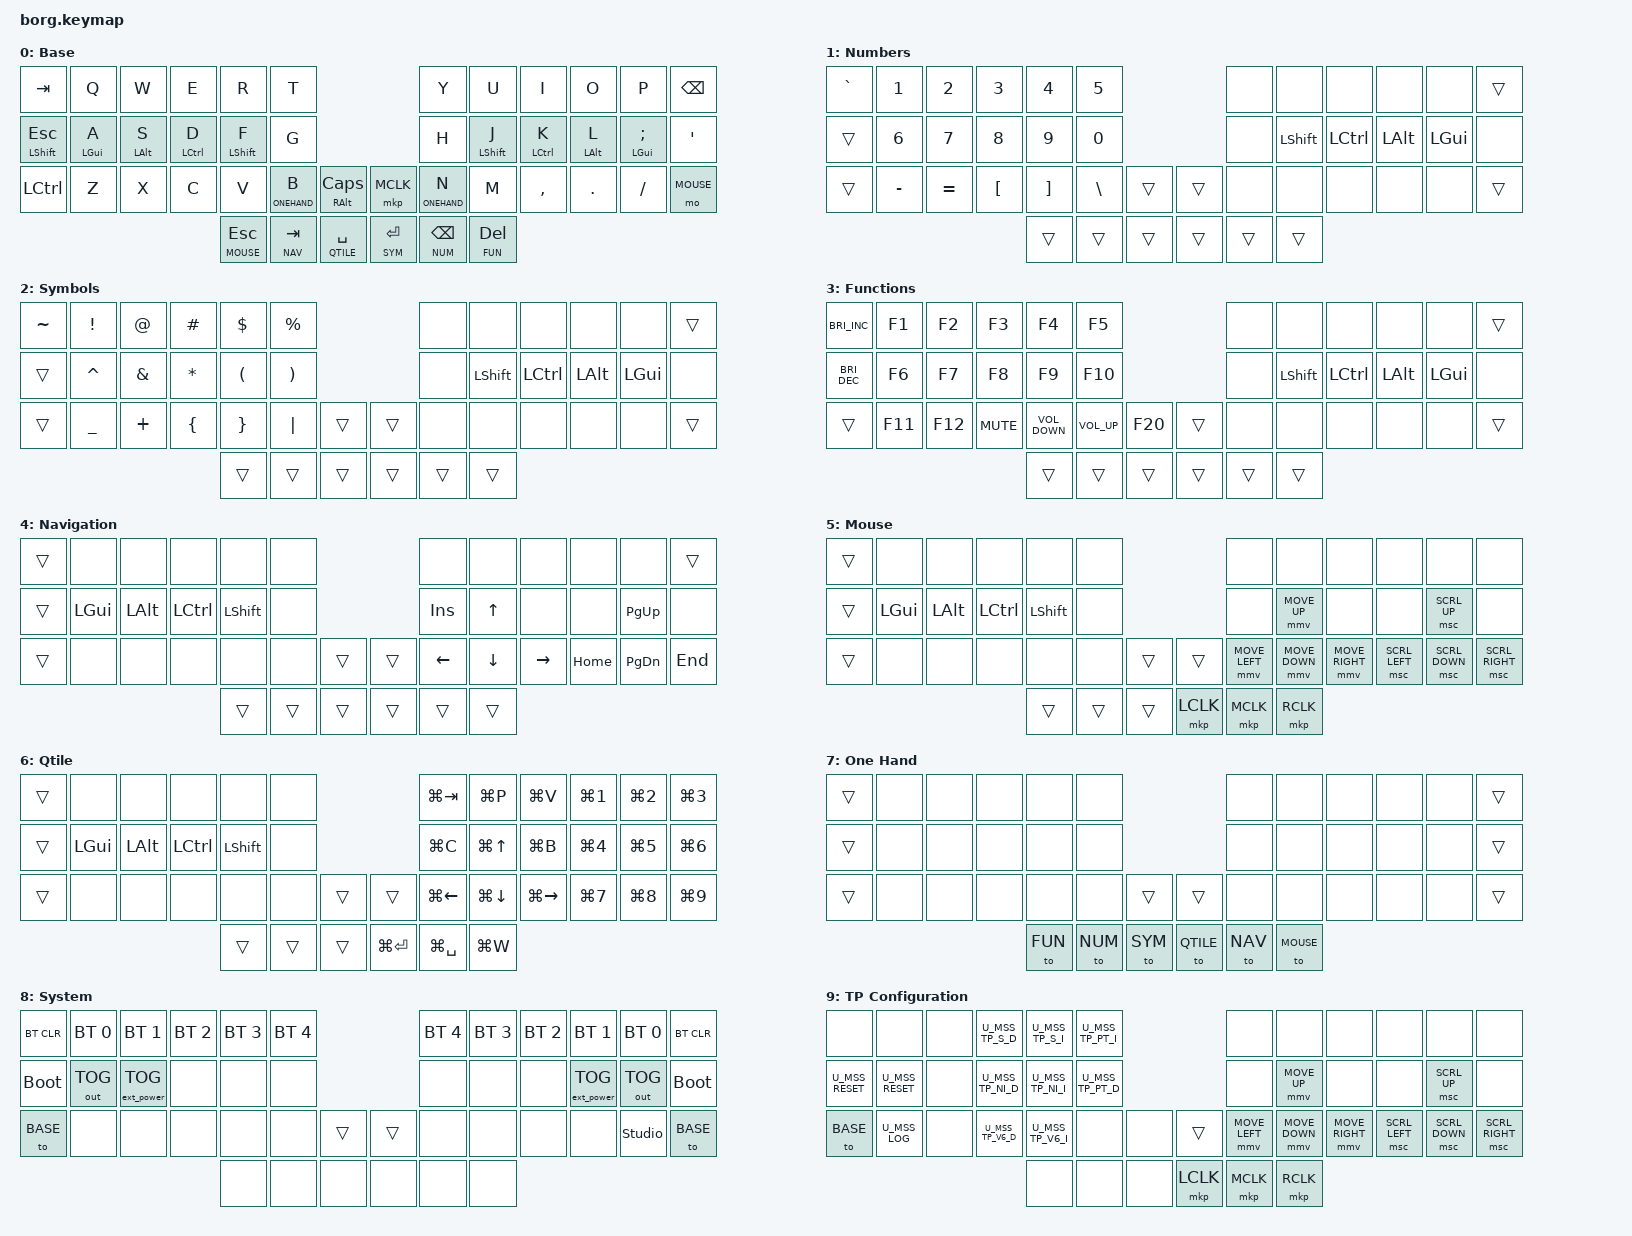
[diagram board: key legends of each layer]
/*
 * Copyright (c) 2020 The ZMK Contributors
 *
 * SPDX-License-Identifier: MIT
 */

#define BASE 0
#define NUM 1
#define SYM 2
#define FUN 3
#define NAV 4
#define MOUSE 5
#define QTILE 6
#define ONEHAND 7
#define SYS 8
#define TPCONF 9

// Change mouse default parameters
//#define ZMK_POINTING_DEFAULT_MOVE_VAL 1200  // 600
#define ZMK_POINTING_DEFAULT_SCRL_VAL 25   // 10

#include <input/processors.dtsi>
#include <behaviors.dtsi>
#include <dt-bindings/zmk/keys.h>
#include <dt-bindings/zmk/bt.h>
#include <dt-bindings/zmk/pointing.h>
#include <dt-bindings/zmk/outputs.h>
#include <dt-bindings/zmk/mouse.h>
#include <behaviors/mouse_keys.dtsi>
#include "include/mouse_tp.dtsi"
#include <dt-bindings/zmk/ext_power.h>

// Double the speed of scrolling
&msc_input_listener { input-processors = <&zip_scroll_scaler 2 1>; };

/*
    &msc {
        acceleration-exponent = <1>;      // 0
        time-to-max-speed-ms = <100>;       // 300
        delay-ms = <0>;                   // 0
    };
*/

// Disable line-wrap in your editor to see a "visualization" of the key layouts
/ {
    combos {
        compatible = "zmk,combos";

        combo_base_layer_right {
            timeout-ms = <50>;
            key-positions = <32 33>;
            bindings = <&to BASE>;
        };
        combo_base_layer_left {
            timeout-ms = <50>;
            key-positions = <28 29>;
            bindings = <&to BASE>;
        };
        combo_sys_layer {
            timeout-ms = <50>;
            key-positions = <18 32>;
            bindings = <&to SYS>;
        };
        combo_tpconf_layer {
            timeout-ms = <50>;
            key-positions = <19 33>;
            bindings = <&to TPCONF>;
        };
    };

    behaviors {
        mouse_wheel: mouse_wheel {
            compatible = "zmk,behavior-sensor-rotate";
            #sensor-binding-cells = <0>;
            bindings = <&msc SCRL_UP>, <&msc SCRL_DOWN>;
            tap-ms = <100>;
        };

        u_lt: u_layer_tap {
            compatible = "zmk,behavior-hold-tap";
            #binding-cells = <2>;
            flavor = "tap-preferred";
            tapping-term-ms = <200>;
            quick-tap-ms = <200>;
            bindings = < &mo >, < &kp >;
        };

        u_mt: u_mod_tap {
            compatible = "zmk,behavior-hold-tap";
            #binding-cells = <2>;
            flavor = "balanced";
            tapping-term-ms = <150>;
            bindings = < &kp >, < &kp >;
        };

    };

    keymap {
        compatible = "zmk,keymap";

        Base_layer {
            display-name = "Base";
            bindings = <
//     ╭────────────────────────┬────────────────────────┬────────────────────────┬────────────────────────┬────────────────────────┬────────────────────────╮                                                      ╭────────────────────────┬────────────────────────┬────────────────────────┬────────────────────────┬────────────────────────┬────────────────────────╮
         &kp TAB                  &kp Q                    &kp W                    &kp E                    &kp R                    &kp T                                                                           &kp Y                    &kp U                    &kp I                    &kp O                    &kp P                    &kp BSPC
//     ├────────────────────────┼────────────────────────┼────────────────────────┼────────────────────────┼────────────────────────┼────────────────────────┤                                                      ├────────────────────────┼────────────────────────┼────────────────────────┼────────────────────────┼────────────────────────┼────────────────────────┤
         &u_mt LSHFT ESC          &u_mt LGUI A             &u_mt LALT S             &u_mt LCTRL D            &u_mt LSHFT F            &kp G                                                                           &kp H                    &u_mt LSHFT J            &u_mt LCTRL K            &u_mt LALT L             &u_mt LGUI SEMI          &kp SQT           
//     ├────────────────────────┼────────────────────────┼────────────────────────┼────────────────────────┼────────────────────────┼────────────────────────┼────────────────────────╮    ╭────────────────────────┼────────────────────────┼────────────────────────┼────────────────────────┼────────────────────────┼────────────────────────┼────────────────────────┤
         &kp LCTRL                &kp Z                    &kp X                    &kp C                    &kp V                    &u_lt ONEHAND B          &u_mt RALT CAPS               &mkp MCLK                &u_lt ONEHAND N          &kp M                    &kp COMMA                &kp DOT                  &kp SLASH                &mo MOUSE
//     ╰────────────────────────┴────────────────────────┴────────────────────────┴────────────────────────┼────────────────────────┼────────────────────────┼────────────────────────┤    ├────────────────────────┼────────────────────────┼────────────────────────┼────────────────────────┴────────────────────────┴────────────────────────┴────────────────────────╯
                                                                                                             &u_lt MOUSE ESC          &u_lt NAV TAB            &u_lt QTILE SPACE             &u_lt SYM RET            &u_lt NUM BSPC           &u_lt FUN DEL
//                                                                                                         ╰────────────────────────┴────────────────────────┴────────────────────────╯    ╰────────────────────────┴────────────────────────┴────────────────────────╯
            >;
        sensor-bindings = <&mouse_wheel>;
        };

        Numbers_layer {
            display-name = "Numbers";
            bindings = <
//     ╭────────────────────────┬────────────────────────┬────────────────────────┬────────────────────────┬────────────────────────┬────────────────────────╮                                                      ╭────────────────────────┬────────────────────────┬────────────────────────┬────────────────────────┬────────────────────────┬────────────────────────╮
         &kp GRAVE                &kp N1                   &kp N2                   &kp N3                   &kp N4                   &kp N5                                                                          &none                    &none                    &none                    &none                    &none                    &trans
//     ├────────────────────────┼────────────────────────┼────────────────────────┼────────────────────────┼────────────────────────┼────────────────────────┤                                                      ├────────────────────────┼────────────────────────┼────────────────────────┼────────────────────────┼────────────────────────┼────────────────────────┤
         &trans                   &kp N6                   &kp N7                   &kp N8                   &kp N9                   &kp N0                                                                          &none                    &kp LSHFT                &kp LCTRL                &kp LALT                 &kp LGUI                 &none
//     ├────────────────────────┼────────────────────────┼────────────────────────┼────────────────────────┼────────────────────────┼────────────────────────┼────────────────────────╮    ╭────────────────────────┼────────────────────────┼────────────────────────┼────────────────────────┼────────────────────────┼────────────────────────┼────────────────────────┤
         &trans                   &kp MINUS                &kp EQUAL                &kp LEFT_BRACKET         &kp RIGHT_BRACKET        &kp BACKSLASH            &trans                        &trans                   &none                    &none                    &none                    &none                    &none                    &trans
//     ╰────────────────────────┴────────────────────────┴────────────────────────┴────────────────────────┼────────────────────────┼────────────────────────┼────────────────────────┤    ├────────────────────────┼────────────────────────┼────────────────────────┼────────────────────────┴────────────────────────┴────────────────────────┴────────────────────────╯
                                                                                                             &trans                   &trans                   &trans                        &trans                   &trans                   &trans
//                                                                                                         ╰────────────────────────┴────────────────────────┴────────────────────────╯    ╰────────────────────────┴────────────────────────┴────────────────────────╯
            >;
        };

        Symbols_layer {
            display-name = "Symbols";
            bindings = <
//     ╭────────────────────────┬────────────────────────┬────────────────────────┬────────────────────────┬────────────────────────┬────────────────────────╮                                                      ╭────────────────────────┬────────────────────────┬────────────────────────┬────────────────────────┬────────────────────────┬────────────────────────╮
         &kp TILDE                &kp EXCLAMATION          &kp AT                   &kp HASH                 &kp DOLLAR               &kp PERCENT                                                                     &none                    &none                    &none                    &none                    &none                    &trans
//     ├────────────────────────┼────────────────────────┼────────────────────────┼────────────────────────┼────────────────────────┼────────────────────────┤                                                      ├────────────────────────┼────────────────────────┼────────────────────────┼────────────────────────┼────────────────────────┼────────────────────────┤
         &trans                   &kp CARET                &kp AMPERSAND            &kp ASTERISK             &kp LEFT_PARENTHESIS     &kp RIGHT_PARENTHESIS                                                           &none                    &kp LSHFT                &kp LCTRL                &kp LALT                 &kp LGUI                 &none
//     ├────────────────────────┼────────────────────────┼────────────────────────┼────────────────────────┼────────────────────────┼────────────────────────┼────────────────────────╮    ╭────────────────────────┼────────────────────────┼────────────────────────┼────────────────────────┼────────────────────────┼────────────────────────┼────────────────────────┤
         &trans                   &kp UNDERSCORE           &kp PLUS                 &kp LEFT_BRACE           &kp RIGHT_BRACE          &kp PIPE                 &trans                        &trans                   &none                    &none                    &none                    &none                    &none                    &trans
//     ╰────────────────────────┴────────────────────────┴────────────────────────┴────────────────────────┼────────────────────────┼────────────────────────┼────────────────────────┤    ├────────────────────────┼────────────────────────┼────────────────────────┼────────────────────────┴────────────────────────┴────────────────────────┴────────────────────────╯
                                                                                                             &trans                   &trans                   &trans                        &trans                   &trans                   &trans
//                                                                                                         ╰────────────────────────┴────────────────────────┴────────────────────────╯    ╰────────────────────────┴────────────────────────┴────────────────────────╯
            >;
        };

        Functions_layer {
            display-name = "Functions";
            bindings = <
//     ╭────────────────────────┬────────────────────────┬────────────────────────┬────────────────────────┬────────────────────────┬────────────────────────╮                                                      ╭────────────────────────┬────────────────────────┬────────────────────────┬────────────────────────┬────────────────────────┬────────────────────────╮
         &kp C_BRIGHTNESS_INC     &kp F1                   &kp F2                   &kp F3                   &kp F4                   &kp F5                                                                          &none                    &none                    &none                    &none                    &none                    &trans
//     ├────────────────────────┼────────────────────────┼────────────────────────┼────────────────────────┼────────────────────────┼────────────────────────┤                                                      ├────────────────────────┼────────────────────────┼────────────────────────┼────────────────────────┼────────────────────────┼────────────────────────┤
         &kp C_BRIGHTNESS_DEC     &kp F6                   &kp F7                   &kp F8                   &kp F9                   &kp F10                                                                         &none                    &kp LSHFT                &kp LCTRL                &kp LALT                 &kp LGUI                 &none
//     ├────────────────────────┼────────────────────────┼────────────────────────┼────────────────────────┼────────────────────────┼────────────────────────┼────────────────────────╮    ╭────────────────────────┼────────────────────────┼────────────────────────┼────────────────────────┼────────────────────────┼────────────────────────┼────────────────────────┤
         &trans                   &kp F11                  &kp F12                  &kp K_MUTE               &kp K_VOLUME_DOWN        &kp K_VOLUME_UP          &kp F20                       &trans                   &none                    &none                    &none                    &none                    &none                    &trans
//     ╰────────────────────────┴────────────────────────┴────────────────────────┴────────────────────────┼────────────────────────┼────────────────────────┼────────────────────────┤    ├────────────────────────┼────────────────────────┼────────────────────────┼────────────────────────┴────────────────────────┴────────────────────────┴────────────────────────╯
                                                                                                             &trans                   &trans                   &trans                        &trans                   &trans                   &trans
//                                                                                                         ╰────────────────────────┴────────────────────────┴────────────────────────╯    ╰────────────────────────┴────────────────────────┴────────────────────────╯
            >;
        };

        Navigation_layer {
            display-name = "Navigation";
            bindings = <
//     ╭────────────────────────┬────────────────────────┬────────────────────────┬────────────────────────┬────────────────────────┬────────────────────────╮                                                      ╭────────────────────────┬────────────────────────┬────────────────────────┬────────────────────────┬────────────────────────┬────────────────────────╮
         &trans                   &none                    &none                    &none                    &none                    &none                                                                           &none                    &none                    &none                    &none                    &none                    &trans   
//     ├────────────────────────┼────────────────────────┼────────────────────────┼────────────────────────┼────────────────────────┼────────────────────────┤                                                      ├────────────────────────┼────────────────────────┼────────────────────────┼────────────────────────┼────────────────────────┼────────────────────────┤
         &trans                   &kp LGUI                 &kp LALT                 &kp LCTRL                &kp LSHFT                &none                                                                           &kp INS                  &kp UP                   &none                    &none                    &kp PAGE_UP              &none                   
//     ├────────────────────────┼────────────────────────┼────────────────────────┼────────────────────────┼────────────────────────┼────────────────────────┼────────────────────────╮    ╭────────────────────────┼────────────────────────┼────────────────────────┼────────────────────────┼────────────────────────┼────────────────────────┼────────────────────────┤
         &trans                   &none                    &none                    &none                    &none                    &none                    &trans                        &trans                   &kp LEFT                 &kp DOWN                 &kp RIGHT                &kp HOME                 &kp PAGE_DOWN            &kp END                
//     ╰────────────────────────┴────────────────────────┴────────────────────────┴────────────────────────┼────────────────────────┼────────────────────────┼────────────────────────┤    ├────────────────────────┼────────────────────────┼────────────────────────┼────────────────────────┴────────────────────────┴────────────────────────┴────────────────────────╯
                                                                                                             &trans                   &trans                   &trans                        &trans                   &trans                   &trans
//                                                                                                         ╰────────────────────────┴────────────────────────┴────────────────────────╯    ╰────────────────────────┴────────────────────────┴────────────────────────╯
            >;
        };

        // Also automatically activated when the mouse or trackpoint moves.
        // Configured in `include/mouse_tp.dtsi`.
        Mouse_layer {
            display-name = "Mouse";
            bindings = <
//     ╭────────────────────────┬────────────────────────┬────────────────────────┬────────────────────────┬────────────────────────┬────────────────────────╮                                                      ╭────────────────────────┬────────────────────────┬────────────────────────┬────────────────────────┬────────────────────────┬────────────────────────╮
         &trans                   &none                    &none                    &none                    &none                    &none                                                                           &none                    &none                    &none                    &none                    &none                    &none
//     ├────────────────────────┼────────────────────────┼────────────────────────┼────────────────────────┼────────────────────────┼────────────────────────┤                                                      ├────────────────────────┼────────────────────────┼────────────────────────┼────────────────────────┼────────────────────────┼────────────────────────┤
         &trans                   &kp LGUI                 &kp LALT                 &kp LCTRL                &kp LSHFT                &none                                                                           &none                    &mmv MOVE_UP             &none                    &none                    &msc SCRL_UP             &none             
//     ├────────────────────────┼────────────────────────┼────────────────────────┼────────────────────────┼────────────────────────┼────────────────────────┼────────────────────────╮    ╭────────────────────────┼────────────────────────┼────────────────────────┼────────────────────────┼────────────────────────┼────────────────────────┼────────────────────────┤
         &trans                   &none                    &none                    &none                    &none                    &none                    &trans                        &trans                   &mmv MOVE_LEFT           &mmv MOVE_DOWN           &mmv MOVE_RIGHT          &msc SCRL_LEFT           &msc SCRL_DOWN           &msc SCRL_RIGHT      
//     ╰────────────────────────┴────────────────────────┴────────────────────────┴────────────────────────┼────────────────────────┼────────────────────────┼────────────────────────┤    ├────────────────────────┼────────────────────────┼────────────────────────┼────────────────────────┴────────────────────────┴────────────────────────┴────────────────────────╯
                                                                                                             &trans                   &trans                   &trans                        &mkp LCLK                &mkp MCLK                &mkp RCLK
//                                                                                                         ╰────────────────────────┴────────────────────────┴────────────────────────╯    ╰────────────────────────┴────────────────────────┴────────────────────────╯
            >;
        };

        Qtile_layer {
            display-name = "Qtile";
            bindings = <
//     ╭────────────────────────┬────────────────────────┬────────────────────────┬────────────────────────┬────────────────────────┬────────────────────────╮                                                      ╭────────────────────────┬────────────────────────┬────────────────────────┬────────────────────────┬────────────────────────┬────────────────────────╮
         &trans                   &none                    &none                    &none                    &none                    &none                                                                           &kp LG(TAB)              &kp LG(P)                &kp LG(V)                &kp LG(N1)               &kp LG(N2)               &kp LG(N3) 
//     ├────────────────────────┼────────────────────────┼────────────────────────┼────────────────────────┼────────────────────────┼────────────────────────┤                                                      ├────────────────────────┼────────────────────────┼────────────────────────┼────────────────────────┼────────────────────────┼────────────────────────┤
         &trans                   &kp LGUI                 &kp LALT                 &kp LCTRL                &kp LSHFT                &none                                                                           &kp LG(C)                &kp LG(UP)               &kp LG(B)                &kp LG(N4)               &kp LG(N5)               &kp LG(N6) 
//     ├────────────────────────┼────────────────────────┼────────────────────────┼────────────────────────┼────────────────────────┼────────────────────────┼────────────────────────╮    ╭────────────────────────┼────────────────────────┼────────────────────────┼────────────────────────┼────────────────────────┼────────────────────────┼────────────────────────┤
         &trans                   &none                    &none                    &none                    &none                    &none                    &trans                        &trans                   &kp LG(LEFT)             &kp LG(DOWN)             &kp LG(RIGHT)            &kp LG(N7)               &kp LG(N8)               &kp LG(N9) 
//     ╰────────────────────────┴────────────────────────┴────────────────────────┴────────────────────────┼────────────────────────┼────────────────────────┼────────────────────────┤    ├────────────────────────┼────────────────────────┼────────────────────────┼────────────────────────┴────────────────────────┴────────────────────────┴────────────────────────╯
                                                                                                             &trans                   &trans                   &trans                        &kp LG(RET)              &kp LG(SPACE)            &kp LG(W)
//                                                                                                         ╰────────────────────────┴────────────────────────┴────────────────────────╯    ╰────────────────────────┴────────────────────────┴────────────────────────╯
            >;
        };

        OneHand_layer {
            display-name = "One Hand";
            bindings = <
//     ╭────────────────────────┬────────────────────────┬────────────────────────┬────────────────────────┬────────────────────────┬────────────────────────╮                                                      ╭────────────────────────┬────────────────────────┬────────────────────────┬────────────────────────┬────────────────────────┬────────────────────────╮
         &trans                   &none                    &none                    &none                    &none                    &none                                                                           &none                    &none                    &none                    &none                    &none                    &trans     
//     ├────────────────────────┼────────────────────────┼────────────────────────┼────────────────────────┼────────────────────────┼────────────────────────┤                                                      ├────────────────────────┼────────────────────────┼────────────────────────┼────────────────────────┼────────────────────────┤────────────────────────┤
         &trans                   &none                    &none                    &none                    &none                    &none                                                                           &none                    &none                    &none                    &none                    &none                    &trans     
//     ├────────────────────────┼────────────────────────┼────────────────────────┼────────────────────────┼────────────────────────┼────────────────────────┼────────────────────────╮    ╭────────────────────────┼────────────────────────┼────────────────────────┼────────────────────────┼────────────────────────┼────────────────────────┼────────────────────────┤
         &trans                   &none                    &none                    &none                    &none                    &none                    &trans                        &trans                   &none                    &none                    &none                    &none                    &none                    &trans     
//     ╰────────────────────────┴────────────────────────┴────────────────────────┴────────────────────────┼────────────────────────┼────────────────────────┼────────────────────────┤    ├────────────────────────┼────────────────────────┼────────────────────────┼────────────────────────┴────────────────────────┴────────────────────────┴────────────────────────╯
                                                                                                             &to FUN                  &to NUM                  &to SYM                       &to QTILE                &to NAV                  &to MOUSE
//                                                                                                         ╰────────────────────────┴────────────────────────┴────────────────────────╯    ╰────────────────────────┴────────────────────────┴────────────────────────╯
            >;
        };

        System_layer {
            display-name = "System";
            bindings = <
//     ╭────────────────────────┬────────────────────────┬────────────────────────┬────────────────────────┬────────────────────────┬────────────────────────╮                                                      ╭────────────────────────┬────────────────────────┬────────────────────────┬────────────────────────┬────────────────────────┬────────────────────────╮
         &bt BT_CLR               &bt BT_SEL 0             &bt BT_SEL 1             &bt BT_SEL 2             &bt BT_SEL 3             &bt BT_SEL 4                                                                    &bt BT_SEL 4             &bt BT_SEL 3             &bt BT_SEL 2             &bt BT_SEL 1             &bt BT_SEL 0             &bt BT_CLR
//     ├────────────────────────┼────────────────────────┼────────────────────────┼────────────────────────┼────────────────────────┼────────────────────────┤                                                      ├────────────────────────┼────────────────────────┼────────────────────────┼────────────────────────┼────────────────────────┼────────────────────────┤
         &bootloader              &out OUT_TOG             &ext_power EP_TOG        &none                    &none                    &none                                                                           &none                    &none                    &none                    &ext_power EP_TOG        &out OUT_TOG             &bootloader 
//     ├────────────────────────┼────────────────────────┼────────────────────────┼────────────────────────┼────────────────────────┼────────────────────────┼────────────────────────╮    ╭────────────────────────┼────────────────────────┼────────────────────────┼────────────────────────┼────────────────────────┼────────────────────────┼────────────────────────┤
         &to BASE                 &none                    &none                    &none                    &none                    &none                    &trans                        &trans                   &none                    &none                    &none                    &none                    &studio_unlock           &to BASE
//     ╰────────────────────────┴────────────────────────┴────────────────────────┴────────────────────────┼────────────────────────┼────────────────────────┼────────────────────────┤    ├────────────────────────┼────────────────────────┼────────────────────────┼────────────────────────┴────────────────────────┴────────────────────────┴────────────────────────╯
                                                                                                             &none                    &none                    &none                         &none                    &none                    &none 
//                                                                                                         ╰────────────────────────┴────────────────────────┴────────────────────────╯    ╰────────────────────────┴────────────────────────┴────────────────────────╯
            >;
        };

        // You can find the defines for the actual key press behaviors in `include/mouse_tp.dtsi`.
        TPConf_layer {
            display-name = "TP Configuration";
            bindings = <
//     ╭────────────────────────┬────────────────────────┬────────────────────────┬────────────────────────┬────────────────────────┬────────────────────────╮                                                      ╭────────────────────────┬────────────────────────┬────────────────────────┬────────────────────────┬────────────────────────┬────────────────────────╮
         &none                    &none                    &none                    U_MSS_TP_S_D             U_MSS_TP_S_I             U_MSS_TP_PT_I                                                                   &none                    &none                    &none                    &none                    &none                    &none
//     ├────────────────────────┼────────────────────────┼────────────────────────┼────────────────────────┼────────────────────────┼────────────────────────┤                                                      ├────────────────────────┼────────────────────────┼────────────────────────┼────────────────────────┼────────────────────────┼────────────────────────┤
         U_MSS_RESET              U_MSS_RESET              &none                    U_MSS_TP_NI_D            U_MSS_TP_NI_I            U_MSS_TP_PT_D                                                                   &none                    &mmv MOVE_UP             &none                    &none                    &msc SCRL_UP             &none             
//     ├────────────────────────┼────────────────────────┼────────────────────────┼────────────────────────┼────────────────────────┼────────────────────────┼────────────────────────╮    ╭────────────────────────┼────────────────────────┼────────────────────────┼────────────────────────┼────────────────────────┼────────────────────────┼────────────────────────┤
         &to BASE                 U_MSS_LOG                &none                    U_MSS_TP_V6_D            U_MSS_TP_V6_I            &none                    &none                         &trans                   &mmv MOVE_LEFT           &mmv MOVE_DOWN           &mmv MOVE_RIGHT          &msc SCRL_LEFT           &msc SCRL_DOWN           &msc SCRL_RIGHT      
//     ╰────────────────────────┴────────────────────────┴────────────────────────┴────────────────────────┼────────────────────────┼────────────────────────┼────────────────────────┤    ├────────────────────────┼────────────────────────┼────────────────────────┼────────────────────────┴────────────────────────┴────────────────────────┴────────────────────────╯
                                                                                                             &none                    &none                    &none                         &mkp LCLK                &mkp MCLK                &mkp RCLK
//                                                                                                         ╰────────────────────────┴────────────────────────┴────────────────────────╯    ╰────────────────────────┴────────────────────────┴────────────────────────╯
            >;
        };
    };
};

// vim: nowrap textwidth=0 expandtab tabstop=4
